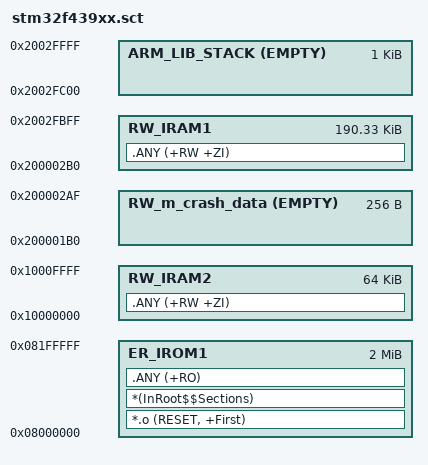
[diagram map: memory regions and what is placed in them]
#! armcc -E
; Scatter-Loading Description File
;;;;;;;;;;;;;;;;;;;;;;;;;;;;;;;;;;;;;;;;;;;;;;;;;;;;;;;;;;;;;;;;;;;;;;;;;;;;;;;;
; Copyright (c) 2015, STMicroelectronics
; All rights reserved.
;
; Redistribution and use in source and binary forms, with or without
; modification, are permitted provided that the following conditions are met:
;
; 1. Redistributions of source code must retain the above copyright notice,
;     this list of conditions and the following disclaimer.
; 2. Redistributions in binary form must reproduce the above copyright notice,
;    this list of conditions and the following disclaimer in the documentation
;    and/or other materials provided with the distribution.
; 3. Neither the name of STMicroelectronics nor the names of its contributors
;    may be used to endorse or promote products derived from this software
;    without specific prior written permission.
;
; THIS SOFTWARE IS PROVIDED BY THE COPYRIGHT HOLDERS AND CONTRIBUTORS "AS IS"
; AND ANY EXPRESS OR IMPLIED WARRANTIES, INCLUDING, BUT NOT LIMITED TO, THE
; IMPLIED WARRANTIES OF MERCHANTABILITY AND FITNESS FOR A PARTICULAR PURPOSE ARE
; DISCLAIMED. IN NO EVENT SHALL THE COPYRIGHT HOLDER OR CONTRIBUTORS BE LIABLE
; FOR ANY DIRECT, INDIRECT, INCIDENTAL, SPECIAL, EXEMPLARY, OR CONSEQUENTIAL
; DAMAGES (INCLUDING, BUT NOT LIMITED TO, PROCUREMENT OF SUBSTITUTE GOODS OR
; SERVICES; LOSS OF USE, DATA, OR PROFITS; OR BUSINESS INTERRUPTION) HOWEVER
; CAUSED AND ON ANY THEORY OF LIABILITY, WHETHER IN CONTRACT, STRICT LIABILITY,
; OR TORT (INCLUDING NEGLIGENCE OR OTHERWISE) ARISING IN ANY WAY OUT OF THE USE
; OF THIS SOFTWARE, EVEN IF ADVISED OF THE POSSIBILITY OF SUCH DAMAGE.
;;;;;;;;;;;;;;;;;;;;;;;;;;;;;;;;;;;;;;;;;;;;;;;;;;;;;;;;;;;;;;;;;;;;;;;;;;;;;;;;

#if !defined(MBED_APP_START)
  #define MBED_APP_START 0x08000000
#endif

#if !defined(MBED_APP_SIZE)
  #define MBED_APP_SIZE 0x200000
#endif

#if !defined(MBED_BOOT_STACK_SIZE)
  #define MBED_BOOT_STACK_SIZE 0x400
#endif

#define Stack_Size MBED_BOOT_STACK_SIZE

#define MBED_RAM_START              0x20000000
#define MBED_RAM_SIZE               0x30000
#define MBED_VECTTABLE_RAM_START    (MBED_RAM_START)
#define MBED_VECTTABLE_RAM_SIZE     0x1B0
#define MBED_CRASH_REPORT_RAM_START (MBED_VECTTABLE_RAM_START + MBED_VECTTABLE_RAM_SIZE)
#define MBED_CRASH_REPORT_RAM_SIZE  0x100
#define MBED_RAM0_START             (MBED_CRASH_REPORT_RAM_START + MBED_CRASH_REPORT_RAM_SIZE)
#define MBED_RAM0_SIZE              (MBED_RAM_SIZE - MBED_VECTTABLE_RAM_SIZE - MBED_CRASH_REPORT_RAM_SIZE)

; 2 MB FLASH (0x200000) + 256 KB SRAM (0x30000 + 0x10000)
LR_IROM1 MBED_APP_START MBED_APP_SIZE  {    ; load region size_region

  ER_IROM1 MBED_APP_START MBED_APP_SIZE  {  ; load address = execution address
   *.o (RESET, +First)
   *(InRoot$$Sections)
   .ANY (+RO)
  }
  
  RW_m_crash_data MBED_CRASH_REPORT_RAM_START EMPTY MBED_CRASH_REPORT_RAM_SIZE { ; RW data
  }

  ; Total: 107 vectors = 428 bytes(0x1AC) 8-byte aligned = 0x1B0 (0x1AC + 0x4) to be reserved in RAM
  RW_IRAM1 (MBED_RAM0_START) (MBED_RAM0_SIZE-Stack_Size)  {  ; RW data
   .ANY (+RW +ZI)
  }
  
  RW_IRAM2 (0x10000000) (0x10000)  {  ; RW data
   .ANY (+RW +ZI)
  }

  ARM_LIB_STACK (MBED_RAM0_START+MBED_RAM0_SIZE) EMPTY -Stack_Size { ; stack
  }
}

